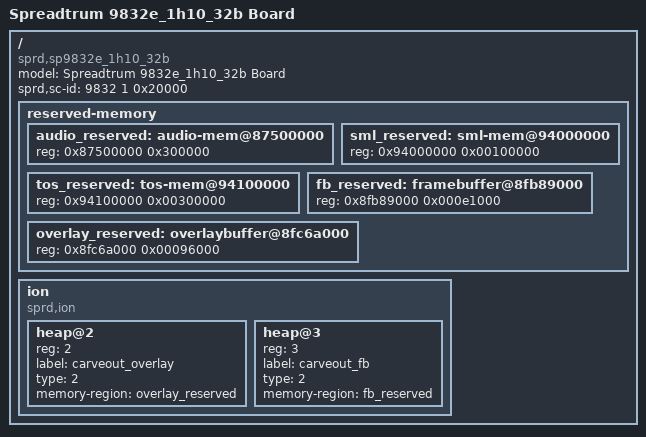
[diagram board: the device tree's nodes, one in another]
/*
 * Spreadtrum SP9860g board DTS file
 *
 * Copyright (C) 2016, Spreadtrum Communications Inc.
 *
 * This file is licensed under a dual GPLv2 or X11 license.
 */

/dts-v1/;

/ {
	model = "Spreadtrum 9832e_1h10_32b Board";

	compatible = "sprd,sp9832e_1h10_32b";

	sprd,sc-id = <9832 1 0x20000>;

	reserved-memory {
		#address-cells = <1>;
		#size-cells = <1>;
		ranges;

		audio_reserved: audio-mem@87500000 {
			reg = <0x87500000 0x300000>;
		};

		/* must be 4K aligned */
		sml_reserved: sml-mem@94000000{
                        reg = <0x94000000 0x00100000>;
                };

                tos_reserved: tos-mem@94100000{
                        reg = <0x94100000 0x00300000>;
                };

		fb_reserved: framebuffer@8fb89000{
			reg = <0x8fb89000 0x000e1000>;
		};

		overlay_reserved: overlaybuffer@8fc6a000{
			reg = <0x8fc6a000 0x00096000>;
		};
	};


	ion {
		compatible = "sprd,ion";
		#address-cells = <1>;
		#size-cells = <0>;

		heap@2 {
			reg = <2>;
			label = "carveout_overlay";
			type = <2>;
			memory-region = <&overlay_reserved>;
		};

		heap@3 {
			reg = <3>;
			label = "carveout_fb";
			type = <2>;
			memory-region = <&fb_reserved>;
		};
	};
};
